# RL6955_IP_SVD register map
Vendor: Realtek
Registers are 32-bit, read-write, reset 0x0 unless marked. A register's access mark holds for its fields unless they carry their own. Offsets are from the block's base; [hi:lo] are bit positions.

## TIMER6_REG
Base 0x41895000
Same registers: TIMER7_REG 0x41895200, TIMER8_REG 0x41895400, TIMER9_REG 0x41895600, TIMER10_REG 0x41895800, UPS_REG 0x41895A00
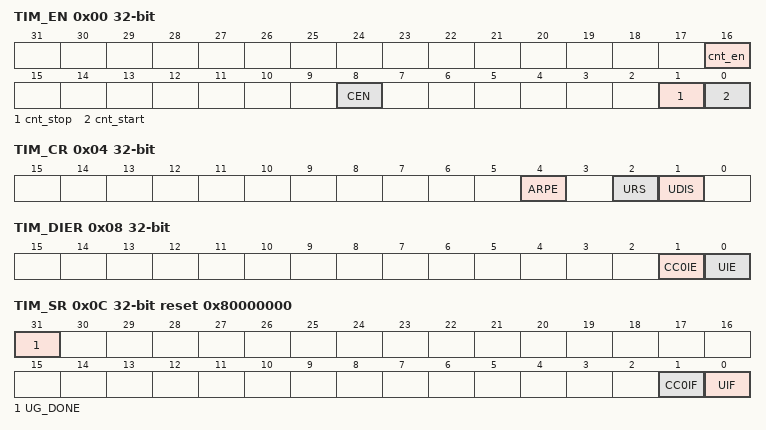
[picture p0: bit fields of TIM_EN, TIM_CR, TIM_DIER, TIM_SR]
0x00 TIM_EN access per field — TIM enable register
  [16] cnt_en ro — counter working status * 0: counter is stoppped * 1: counter is working
  [8] CEN ro — counter run status * 0: counter is disabled * 1: counter is enabled
  [1] cnt_stop wo — disable the counter. Poll CNT_RUN to see the counter status. If CNT_RUN is 0, it means that the counter has been disabled internally.
  [0] cnt_start wo — enable the counter. Poll CNT_RUN to see the counter status. If CNT_RUN is 1, it means that the counter has been enabled internally.
0x04 TIM_CR — TIM control register
  [4] ARPE — enable auto-reload preloading * 0: TIM_ARR register is not buffered * 1: TIM_ARR register is buffered
  [2] URS — update request source * 0: counter overflow and setting the UG bit * 1: counter overflow
  [1] UDIS — disable UEV. Shadow registers keep their values. Otherwise, buffered registers are then loaded with their preload values when UEV happen.
0x08 TIM_DIER — TIM interupt enable register
  [1] CC0IE — enable Capture/Compare 0 interrupt
  [0] UIE — enable update interrupt
0x0C TIM_SR ro reset 0x80000000 — TIM status register
  [31] UG_DONE — UG operation status This bit is cleared by hardware when the UG bit in the TIMx_EGR register is set. When the UG operation is done, hardware set this bit to '1'. So, software can poll this bit to see the UG operation status.
  [1] CC0IF — Capture/Compare 0 interrupt flag CC0 channel configured as pulse mode 0: This bit is set when TRGI is transferred to inactive level from active level. CC0 channel configured as pulse mode 1: This bit is set by hardware when the counter overflows. It is cleared by software.
  [0] UIF — update interrupt flag
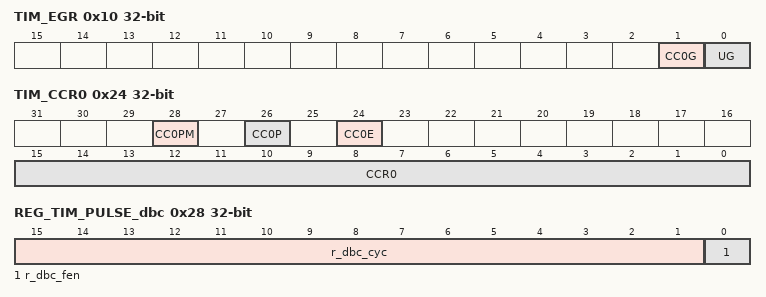
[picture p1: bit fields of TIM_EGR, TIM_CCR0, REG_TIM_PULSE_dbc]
0x10 TIM_EGR wo — TIM event generation register
  [1] CC0G — Capture/Compare 0 generation. This bit is set by software and is automatically cleared by hardware. A Capture/Compare event is generated on channel 0: the current value of the counter is captured in TIM_CCR0 register. The CC0IF flag is set, the corresponding interrupt or request is sent if enabled.
  [0] UG — update generation. Re-initialize the counter and generate an update of registers. Note that the prescaler counter is cleared too.(anyway the prescaler ratio is not affected)
0x14 TIM_CNT ro — TIM counter
  [15:0] CNT — counter value
0x18 TIM_PSC — TIM prescaler register
  [15:0] PSC — prescaler value. PSC contains the value to be loaded in the actual prescaler register at each UEV(including when the counter is cleared through UG bit of TIM_EGR register).
0x1C TIM_ARR reset 0xFFFF — TIM auto-reload register
  [15:0] ARR — the value to be loaded in the actual auto-reload register. It can be preloaded by setting ARPE bit in TIM_CR.
0x24 TIM_CCR0 — TIM Capture register
  [28] CC0PM — CC0 pulse mode * 0: pulse mode 0 * 1: pulse mode 1
  [26] CC0P — CC0 channel configured as output: * 0: OC0 active high * 1: OC0 ative low CC0 channel configured as input: * 0: positive edge of TRGI is active for capture * 1: negative edge of TRGI is active for capture
  [24] CC0E — enable CC0
  [15:0] CCR0 — Capture/Compare 0 value CC0 channel configured as pulse mode 0: the pulse width of TRGI CC0 channel configured as pulse mode 1: the pulse number of TRGI when the counter counts from 0 to ARR
0x28 REG_TIM_PULSE_dbc — Timer Pulse dbc Register
  [15:1] r_dbc_cyc — dbc cycle
  [0] r_dbc_fen — enable debounce for pluse 0:disable 1: enable
0x2C REG_TIM_PULSE_DUMMY reset 0xFFFF — Timer Pulse Dummy Register

## IWDG_REG
Base 0x41000C00
Same registers: WDG0_REG 0x40801D00, WDG2_REG 0x41000D80, WDG1_REG_S 0x51000D40
0x00 WDG_MKEYR — WDG Magic Key register
  [15:0] MKEY — 0x6969: enable access to register WDG_CR/WDG_RLR/WDG_WINR 0x5A5A: reload WDG counter 0x3C3C: enable WDG function
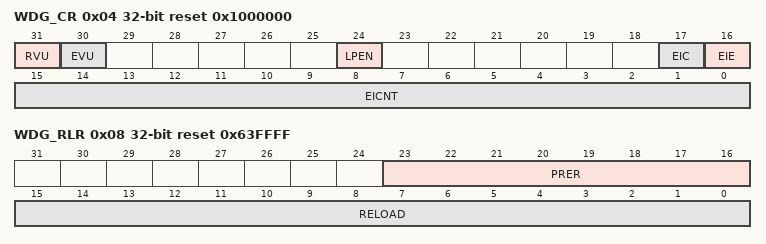
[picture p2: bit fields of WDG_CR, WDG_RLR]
0x04 WDG_CR access per field reset 0x1000000 — WDG Control regsietr
  [31] RVU ro — Watchdog counter update by reload command
  [30] EVU ro — Watchdog early interrupt function update
  [24] LPEN rw — Low power enable 0: WDG will gating when system goes into sleep mode 1: WDG keep running when system goes into sleep mode
  [17] EIC wo — Write '1' clear the early interrupt
  [16] EIE rw — Watchdog early interrupt enable
  [15:0] EICNT rw — Early interrupt trigger threshold
0x08 WDG_RLR reset 0x63FFFF — WDG Relaod register
  [23:16] PRER — Prescaler counter, configuration only allowed before wdg enable WDG: 0x63 System wdg: 0x1F
  [15:0] RELOAD — Reload value for watchdog counter Default : 64s (@100k)
0x0C WDG_WINR reset 0xFFFF — WDG Window Register
  [15:0] WINDOW — Watchdog feed protect window register
0x10 IWDG_DUMMY reset 0xFF — Wdg Dummy Register
  [15:0] dummy — rsvd for hw
